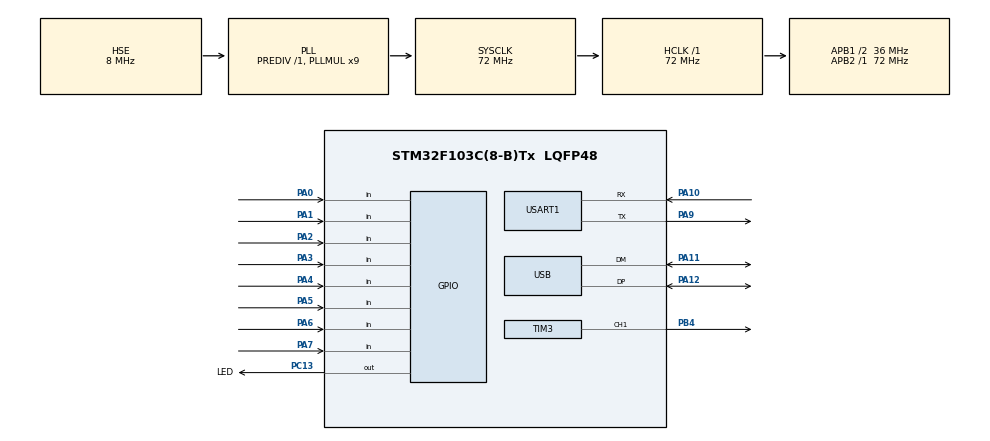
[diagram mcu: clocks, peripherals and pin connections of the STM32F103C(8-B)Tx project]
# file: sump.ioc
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Dma.Request0=TIM1_UP
Dma.TIM1_UP.0.Direction=DMA_PERIPH_TO_MEMORY
Dma.TIM1_UP.0.Instance=DMA1_Channel5
Dma.TIM1_UP.0.MemDataAlignment=DMA_MDATAALIGN_BYTE
Dma.TIM1_UP.0.MemInc=DMA_MINC_ENABLE
Dma.TIM1_UP.0.Mode=DMA_NORMAL
Dma.TIM1_UP.0.PeriphDataAlignment=DMA_PDATAALIGN_WORD
Dma.TIM1_UP.0.PeriphInc=DMA_PINC_DISABLE
Dma.TIM1_UP.0.Priority=DMA_PRIORITY_VERY_HIGH
Mcu.Family=STM32F1
Mcu.Name=STM32F103C(8-B)Tx
Mcu.Package=LQFP48
NVIC.DMA1_Channel5_IRQn=true\:0\:0\:false\:false\:true
NVIC.PriorityGroup=NVIC_PRIORITYGROUP_4
NVIC.USB_HP_CAN1_TX_IRQn=true\:1\:0\:true\:false\:true
NVIC.USB_LP_CAN1_RX0_IRQn=true\:2\:0\:true\:false\:true
PA0-WKUP.Signal=GPIO_Input
PA1.Signal=GPIO_Input
PA10.Mode=Asynchronous
PA10.Signal=USART1_RX
PA11.Mode=Device
PA11.Signal=USB_DM
PA12.Mode=Device
PA12.Signal=USB_DP
PA13.Mode=Serial_Wire
PA13.Signal=SYS_JTMS-SWDIO
PA14.Mode=Serial_Wire
PA14.Signal=SYS_JTCK-SWCLK
PA2.Signal=GPIO_Input
PA3.Signal=GPIO_Input
PA4.Signal=GPIO_Input
PA5.Signal=GPIO_Input
PA6.Signal=GPIO_Input
PA7.Signal=GPIO_Input
PA9.Mode=Asynchronous
PA9.Signal=USART1_TX
PB4.Signal=S_TIM3_CH1
PC13-TAMPER-RTC.GPIO_Label=LED
PC13-TAMPER-RTC.GPIO_ModeDefaultOutputPP=GPIO_MODE_OUTPUT_OD
PC13-TAMPER-RTC.Signal=GPIO_Output
PC14-OSC32_IN.Mode=LSE-External-Oscillator
PC14-OSC32_IN.Signal=RCC_OSC32_IN
PC15-OSC32_OUT.Mode=LSE-External-Oscillator
PC15-OSC32_OUT.Signal=RCC_OSC32_OUT
PD0-OSC_IN.Mode=HSE-External-Oscillator
PD0-OSC_IN.Signal=RCC_OSC_IN
PD1-OSC_OUT.Mode=HSE-External-Oscillator
PD1-OSC_OUT.Signal=RCC_OSC_OUT
ProjectManager.HeapSize=0x0
ProjectManager.StackSize=0x400
ProjectManager.TargetToolchain=SW4STM32
RCC.AHBFreq_Value=72000000
RCC.APB1CLKDivider=RCC_HCLK_DIV2
RCC.APB1Freq_Value=36000000
RCC.APB1TimFreq_Value=72000000
RCC.APB2Freq_Value=72000000
RCC.APB2TimFreq_Value=72000000
RCC.ClockTypeHCLK=RCC_CLOCKTYPE_HCLK
RCC.ClockTypePCLK1=RCC_CLOCKTYPE_PCLK1
RCC.ClockTypePCLK2=RCC_CLOCKTYPE_PCLK2
RCC.EnableHSE=true
RCC.EnableHSERTCDevisor=true
RCC.EnableLSE=true
RCC.EnableLSERTC=true
RCC.EnableMCOMultDivisor=false
RCC.HCLKFreq_Value=72000000
RCC.HSEState=RCC_HSE_ON
RCC.HSIState=RCC_HSI_ON
RCC.IWDGEnable=false
RCC.LSEState=RCC_LSE_ON
RCC.LSIState=RCC_LSI_OFF
RCC.MCOEnable=false
RCC.OscillatorTypeHSE=RCC_OSCILLATORTYPE_HSE
RCC.OscillatorTypeLSE=RCC_OSCILLATORTYPE_LSE
RCC.PLLMUL=RCC_PLL_MUL9
RCC.PLLSource=RCC_PLLSOURCE_HSE
RCC.PLLSourceVirtual=RCC_PLLSOURCE_HSE
RCC.PLLState=RCC_PLL_ON
RCC.RCC_PERIPHCLK_RTCVar=RCC_PERIPHCLK_RTC
RCC.RTCClockSelection=RCC_RTCCLKSOURCE_LSE
RCC.RTCEnable=true
RCC.SYSCLKFreq_VALUE=72000000
RCC.SYSCLKSource=RCC_SYSCLKSOURCE_PLLCLK
RCC.USBFreq_Value=48000000
RCC.USBPrescaler=RCC_USBCLKSOURCE_PLL_DIV1_5
RTC.OutPut=RTC_OUTPUTSOURCE_ALARM
SH.S_TIM3_CH1.0=TIM3_CH1,PWM Generation1 CH1
TIM1.Period=11
TIM1.Prescaler=0
TIM3.Channel-PWM\ Generation1\ CH1=TIM_CHANNEL_1
TIM3.Period=719
TIM3.Pulse-PWM\ Generation1\ CH1=360
USART1.HwFlowCtl-Asynchronous=UART_HWCONTROL_NONE
USART1.VirtualMode=VM_ASYNC
USB.ep0_mps=DEP0CTL_MPS_64
USB_DEVICE.CLASS_NAME_FS=CDC
USB_DEVICE.USBD_HandleTypeDef=hUsbDeviceFS
USB_DEVICE.USBD_HandleTypeDef_FS=hUsbDevice_USB_FS
USB_DEVICE.VirtualMode=Cdc
USB_DEVICE.VirtualModeFS=Cdc_FS
VP_RTC_VS_RTC_Activate.Mode=RTC_Enabled
VP_TIM1_VS_ClockSourceINT.Mode=Internal
VP_TIM3_VS_ClockSourceINT.Mode=Internal
VP_USB_DEVICE_VS_USB_DEVICE_CDC_FS.Mode=CDC_FS
board=sump

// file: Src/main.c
/**
  ******************************************************************************
  * File Name          : main.c
  * Description        : Main program body
  ******************************************************************************
  *
  * Copyright (c) 2017 STMicroelectronics International N.V.
  * All rights reserved.
  *
  * Redistribution and use in source and binary forms, with or without
  * modification, are permitted, provided that the following conditions are met:
  *
  * 1. Redistribution of source code must retain the above copyright notice,
  *    this list of conditions and the following disclaimer.
  * 2. Redistributions in binary form must reproduce the above copyright notice,
  *    this list of conditions and the following disclaimer in the documentation
  *    and/or other materials provided with the distribution.
  * 3. Neither the name of STMicroelectronics nor the names of other
  *    contributors to this software may be used to endorse or promote products
  *    derived from this software without specific written permission.
  * 4. This software, including modifications and/or derivative works of this
  *    software, must execute solely and exclusively on microcontroller or
  *    microprocessor devices manufactured by or for STMicroelectronics.
  * 5. Redistribution and use of this software other than as permitted under
  *    this license is void and will automatically terminate your rights under
  *    this license.
  *
  * THIS SOFTWARE IS PROVIDED BY STMICROELECTRONICS AND CONTRIBUTORS "AS IS"
  * AND ANY EXPRESS, IMPLIED OR STATUTORY WARRANTIES, INCLUDING, BUT NOT
  * LIMITED TO, THE IMPLIED WARRANTIES OF MERCHANTABILITY, FITNESS FOR A
  * PARTICULAR PURPOSE AND NON-INFRINGEMENT OF THIRD PARTY INTELLECTUAL PROPERTY
  * RIGHTS ARE DISCLAIMED TO THE FULLEST EXTENT PERMITTED BY LAW. IN NO EVENT
  * SHALL STMICROELECTRONICS OR CONTRIBUTORS BE LIABLE FOR ANY DIRECT, INDIRECT,
  * INCIDENTAL, SPECIAL, EXEMPLARY, OR CONSEQUENTIAL DAMAGES (INCLUDING, BUT NOT
  * LIMITED TO, PROCUREMENT OF SUBSTITUTE GOODS OR SERVICES; LOSS OF USE, DATA,
  * OR PROFITS; OR BUSINESS INTERRUPTION) HOWEVER CAUSED AND ON ANY THEORY OF
  * LIABILITY, WHETHER IN CONTRACT, STRICT LIABILITY, OR TORT (INCLUDING
  * NEGLIGENCE OR OTHERWISE) ARISING IN ANY WAY OUT OF THE USE OF THIS SOFTWARE,
  * EVEN IF ADVISED OF THE POSSIBILITY OF SUCH DAMAGE.
  *
  ******************************************************************************
  */
#include "main.h"
#include "stm32f1xx_hal.h"
#include "usb_device.h"

/* USER CODE BEGIN Includes */
#include "syscall.h"
#include "usbd_cdc_if.h"
#include "gpio.h"
#include "uart.h"
#include "sump.h"
/* USER CODE END Includes */

RTC_HandleTypeDef hrtc;

TIM_HandleTypeDef htim1;
TIM_HandleTypeDef htim3;
DMA_HandleTypeDef hdma_tim1_up;

UART_HandleTypeDef huart1;

/* USER CODE BEGIN PV */
/* Private variables ---------------------------------------------------------*/

/* USER CODE END PV */

void SystemClock_Config(void);
void Error_Handler(void);
static void MX_GPIO_Init(void);
static void MX_DMA_Init(void);
static void MX_RTC_Init(void);
static void MX_USART1_UART_Init(void);
static void MX_TIM1_Init(void);
static void MX_TIM3_Init(void);

void HAL_TIM_MspPostInit(TIM_HandleTypeDef *htim);

/* USER CODE BEGIN PFP */
/* Private function prototypes -----------------------------------------------*/

/* USER CODE END PFP */

int main(void)
{

  /* MCU Configuration----------------------------------------------------------*/

  /* Reset of all peripherals, Initializes the Flash interface and the Systick. */
  HAL_Init();

  /* Configure the system clock */
  SystemClock_Config();

  /* Initialize all configured peripherals */
  MX_GPIO_Init();
  MX_DMA_Init();
  MX_USB_DEVICE_Init();
  MX_RTC_Init();
  MX_USART1_UART_Init();
  MX_TIM1_Init();
  MX_TIM3_Init();

  /* USER CODE BEGIN 2 */
  // turn off buffers, this costs 1032 bytes of ram
  setvbuf(stdin, NULL, _IONBF, 0);
  setvbuf(stdout, NULL, _IONBF, 0);
  setvbuf(stderr, NULL, _IONBF, 0);
  HAL_TIM_Base_Start(&htim1);
  // setup test PWM output
  HAL_TIM_Base_Start(&htim3);
  HAL_TIM_PWM_Start(&htim3, TIM_CHANNEL_1);
  write_uart_s("\nstarting\n");
  /* USER CODE END 2 */

  /* Infinite loop */
  while (1)
  {

  /* USER CODE BEGIN 3 */
    poll_sump();
  }
  /* USER CODE END 3 */

}

/** System Clock Configuration
*/
void SystemClock_Config(void)
{

  RCC_OscInitTypeDef RCC_OscInitStruct;
  RCC_ClkInitTypeDef RCC_ClkInitStruct;
  RCC_PeriphCLKInitTypeDef PeriphClkInit;

    /**Initializes the CPU, AHB and APB busses clocks
    */
  RCC_OscInitStruct.OscillatorType = RCC_OSCILLATORTYPE_HSE|RCC_OSCILLATORTYPE_LSE;
  RCC_OscInitStruct.HSEState = RCC_HSE_ON;
  RCC_OscInitStruct.HSEPredivValue = RCC_HSE_PREDIV_DIV1;
  RCC_OscInitStruct.LSEState = RCC_LSE_ON;
  RCC_OscInitStruct.PLL.PLLState = RCC_PLL_ON;
  RCC_OscInitStruct.PLL.PLLSource = RCC_PLLSOURCE_HSE;
  RCC_OscInitStruct.PLL.PLLMUL = RCC_PLL_MUL9;
  if (HAL_RCC_OscConfig(&RCC_OscInitStruct) != HAL_OK)
  {
    Error_Handler();
  }

    /**Initializes the CPU, AHB and APB busses clocks
    */
  RCC_ClkInitStruct.ClockType = RCC_CLOCKTYPE_HCLK|RCC_CLOCKTYPE_SYSCLK
                              |RCC_CLOCKTYPE_PCLK1|RCC_CLOCKTYPE_PCLK2;
  RCC_ClkInitStruct.SYSCLKSource = RCC_SYSCLKSOURCE_PLLCLK;
  RCC_ClkInitStruct.AHBCLKDivider = RCC_SYSCLK_DIV1;
  RCC_ClkInitStruct.APB1CLKDivider = RCC_HCLK_DIV2;
  RCC_ClkInitStruct.APB2CLKDivider = RCC_HCLK_DIV1;

  if (HAL_RCC_ClockConfig(&RCC_ClkInitStruct, FLASH_LATENCY_2) != HAL_OK)
  {
    Error_Handler();
  }

  PeriphClkInit.PeriphClockSelection = RCC_PERIPHCLK_RTC|RCC_PERIPHCLK_USB;
  PeriphClkInit.RTCClockSelection = RCC_RTCCLKSOURCE_LSE;
  PeriphClkInit.UsbClockSelection = RCC_USBCLKSOURCE_PLL_DIV1_5;
  if (HAL_RCCEx_PeriphCLKConfig(&PeriphClkInit) != HAL_OK)
  {
    Error_Handler();
  }

    /**Configure the Systick interrupt time
    */
  HAL_SYSTICK_Config(HAL_RCC_GetHCLKFreq()/1000);

    /**Configure the Systick
    */
  HAL_SYSTICK_CLKSourceConfig(SYSTICK_CLKSOURCE_HCLK);

  /* SysTick_IRQn interrupt configuration */
  HAL_NVIC_SetPriority(SysTick_IRQn, 0, 0);
}

/* RTC init function */
static void MX_RTC_Init(void)
{

    /**Initialize RTC Only
    */
  hrtc.Instance = RTC;
  hrtc.Init.AsynchPrediv = RTC_AUTO_1_SECOND;
  hrtc.Init.OutPut = RTC_OUTPUTSOURCE_ALARM;
  if (HAL_RTC_Init(&hrtc) != HAL_OK)
  {
    Error_Handler();
  }

}

/* TIM1 init function */
static void MX_TIM1_Init(void)
{

  TIM_ClockConfigTypeDef sClockSourceConfig;
  TIM_MasterConfigTypeDef sMasterConfig;

  htim1.Instance = TIM1;
  htim1.Init.Prescaler = 0;
  htim1.Init.CounterMode = TIM_COUNTERMODE_UP;
  htim1.Init.Period = 11;
  htim1.Init.ClockDivision = TIM_CLOCKDIVISION_DIV1;
  htim1.Init.RepetitionCounter = 0;
  if (HAL_TIM_Base_Init(&htim1) != HAL_OK)
  {
    Error_Handler();
  }

  sClockSourceConfig.ClockSource = TIM_CLOCKSOURCE_INTERNAL;
  if (HAL_TIM_ConfigClockSource(&htim1, &sClockSourceConfig) != HAL_OK)
  {
    Error_Handler();
  }

  sMasterConfig.MasterOutputTrigger = TIM_TRGO_RESET;
  sMasterConfig.MasterSlaveMode = TIM_MASTERSLAVEMODE_DISABLE;
  if (HAL_TIMEx_MasterConfigSynchronization(&htim1, &sMasterConfig) != HAL_OK)
  {
    Error_Handler();
  }

}

/* TIM3 init function */
static void MX_TIM3_Init(void)
{

  TIM_ClockConfigTypeDef sClockSourceConfig;
  TIM_MasterConfigTypeDef sMasterConfig;
  TIM_OC_InitTypeDef sConfigOC;

  htim3.Instance = TIM3;
  htim3.Init.Prescaler = 0;
  htim3.Init.CounterMode = TIM_COUNTERMODE_UP;
  htim3.Init.Period = 719;
  htim3.Init.ClockDivision = TIM_CLOCKDIVISION_DIV1;
  if (HAL_TIM_Base_Init(&htim3) != HAL_OK)
  {
    Error_Handler();
  }

  sClockSourceConfig.ClockSource = TIM_CLOCKSOURCE_INTERNAL;
  if (HAL_TIM_ConfigClockSource(&htim3, &sClockSourceConfig) != HAL_OK)
  {
    Error_Handler();
  }

  if (HAL_TIM_PWM_Init(&htim3) != HAL_OK)
  {
    Error_Handler();
  }

  sMasterConfig.MasterOutputTrigger = TIM_TRGO_RESET;
  sMasterConfig.MasterSlaveMode = TIM_MASTERSLAVEMODE_DISABLE;
  if (HAL_TIMEx_MasterConfigSynchronization(&htim3, &sMasterConfig) != HAL_OK)
  {
    Error_Handler();
  }

  sConfigOC.OCMode = TIM_OCMODE_PWM1;
  sConfigOC.Pulse = 360;
  sConfigOC.OCPolarity = TIM_OCPOLARITY_HIGH;
  sConfigOC.OCFastMode = TIM_OCFAST_DISABLE;
  if (HAL_TIM_PWM_ConfigChannel(&htim3, &sConfigOC, TIM_CHANNEL_1) != HAL_OK)
  {
    Error_Handler();
  }

  HAL_TIM_MspPostInit(&htim3);

}

/* USART1 init function */
static void MX_USART1_UART_Init(void)
{

  huart1.Instance = USART1;
  huart1.Init.BaudRate = 115200;
  huart1.Init.WordLength = UART_WORDLENGTH_8B;
  huart1.Init.StopBits = UART_STOPBITS_1;
  huart1.Init.Parity = UART_PARITY_NONE;
  huart1.Init.Mode = UART_MODE_TX_RX;
  huart1.Init.HwFlowCtl = UART_HWCONTROL_NONE;
  huart1.Init.OverSampling = UART_OVERSAMPLING_16;
  if (HAL_UART_Init(&huart1) != HAL_OK)
  {
    Error_Handler();
  }

}

static void MX_DMA_Init(void)
{
  /* DMA controller clock enable */
  __HAL_RCC_DMA1_CLK_ENABLE();

  /* DMA interrupt init */
  /* DMA1_Channel5_IRQn interrupt configuration */
  HAL_NVIC_SetPriority(DMA1_Channel5_IRQn, 0, 0);
  HAL_NVIC_EnableIRQ(DMA1_Channel5_IRQn);

}

/** Configure pins as
        * Analog
        * Input
        * Output
        * EVENT_OUT
        * EXTI
*/
static void MX_GPIO_Init(void)
{

  GPIO_InitTypeDef GPIO_InitStruct;

  /* GPIO Ports Clock Enable */
  __HAL_RCC_GPIOC_CLK_ENABLE();
  __HAL_RCC_GPIOD_CLK_ENABLE();
  __HAL_RCC_GPIOA_CLK_ENABLE();
  __HAL_RCC_GPIOB_CLK_ENABLE();

  /*Configure GPIO pin Output Level */
  HAL_GPIO_WritePin(LED_GPIO_Port, LED_Pin, GPIO_PIN_RESET);

  /*Configure GPIO pin : LED_Pin */
  GPIO_InitStruct.Pin = LED_Pin;
  GPIO_InitStruct.Mode = GPIO_MODE_OUTPUT_OD;
  GPIO_InitStruct.Speed = GPIO_SPEED_FREQ_LOW;
  HAL_GPIO_Init(LED_GPIO_Port, &GPIO_InitStruct);

  /*Configure GPIO pins : PA0 PA1 PA2 PA3
                           PA4 PA5 PA6 PA7 */
  GPIO_InitStruct.Pin = GPIO_PIN_0|GPIO_PIN_1|GPIO_PIN_2|GPIO_PIN_3
                          |GPIO_PIN_4|GPIO_PIN_5|GPIO_PIN_6|GPIO_PIN_7;
  GPIO_InitStruct.Mode = GPIO_MODE_INPUT;
  GPIO_InitStruct.Pull = GPIO_NOPULL;
  HAL_GPIO_Init(GPIOA, &GPIO_InitStruct);

}

void Error_Handler(void)
{
  while(1)
  {
  }
}

/************************ (C) COPYRIGHT STMicroelectronics *****END OF FILE****/
